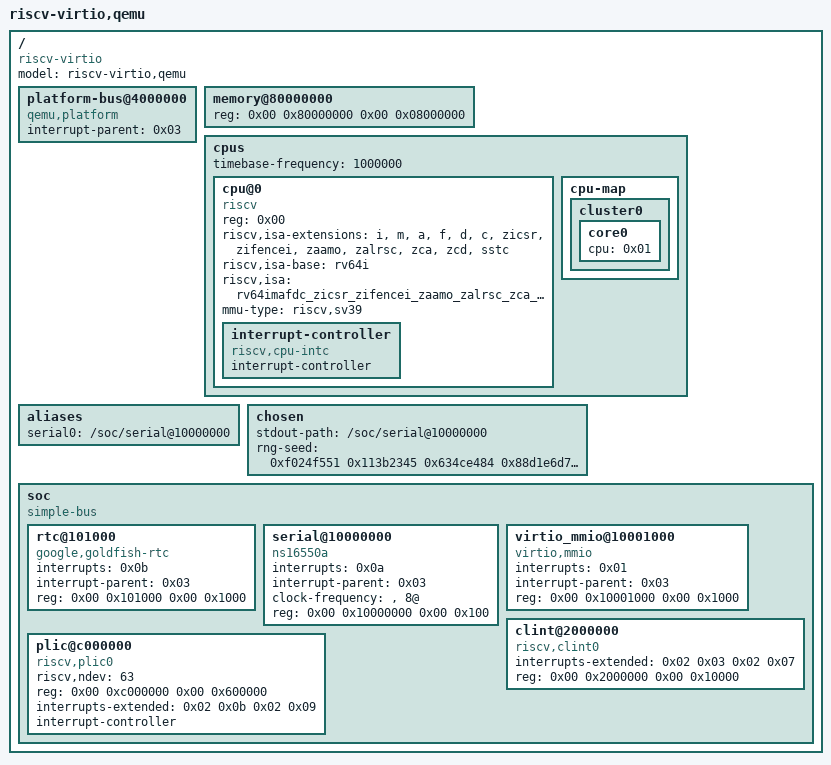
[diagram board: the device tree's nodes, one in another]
/dts-v1/;

/ {
	#address-cells = <0x02>;
	#size-cells = <0x02>;
	compatible = "riscv-virtio";
	model = "riscv-virtio,qemu";

	platform-bus@4000000 {
		interrupt-parent = <0x03>;
		ranges = <0x00 0x00 0x4000000 0x2000000>;
		#address-cells = <0x01>;
		#size-cells = <0x01>;
		compatible = "qemu,platform", "simple-bus";
	};

	memory@80000000 {
		device_type = "memory";
		reg = <0x00 0x80000000 0x00 0x08000000>;
	};

	cpus {
		#address-cells = <0x01>;
		#size-cells = <0x00>;
		timebase-frequency = <1000000>; // 1MHz

		cpu@0 {
			phandle = <0x01>;
			device_type = "cpu";
			reg = <0x00>;
			status = "okay";
			compatible = "riscv";
			riscv,isa-extensions = "i", "m", "a", "f", "d", "c","zicsr", "zifencei", "zaamo", "zalrsc", "zca", "zcd", "sstc";
			riscv,isa-base = "rv64i";
			riscv,isa = "rv64imafdc_zicsr_zifencei_zaamo_zalrsc_zca_zcd_sstc";
			mmu-type = "riscv,sv39";

			interrupt-controller {
				#interrupt-cells = <0x01>;
				interrupt-controller;
				compatible = "riscv,cpu-intc";
				phandle = <0x02>;
			};
		};

		cpu-map {
			cluster0 {
				core0 {
					cpu = <0x01>;
				};
			};
		};
	};

	aliases {
		serial0 = "/soc/serial@10000000";
	};

	chosen {
		stdout-path = "/soc/serial@10000000";
		rng-seed = <0xf024f551 0x113b2345 0x634ce484 0x88d1e6d7 0x4ef455c6 0x78c102fc 0x4ff7a80c 0x13bb7a>;
	};

	soc {
		#address-cells = <0x02>;
		#size-cells = <0x02>;
		compatible = "simple-bus";
		ranges;

		rtc@101000 {
			interrupts = <0x0b>;
			interrupt-parent = <0x03>;
			reg = <0x00 0x101000 0x00 0x1000>;
			compatible = "google,goldfish-rtc";
		};

		serial@10000000 {
			interrupts = <0x0a>;
			interrupt-parent = <0x03>;
			clock-frequency = "", "8@";
			reg = <0x00 0x10000000 0x00 0x100>;
			compatible = "ns16550a";
		};

		virtio_mmio@10001000 {
			interrupts = <0x01>;
			interrupt-parent = <0x03>;
			reg = <0x00 0x10001000 0x00 0x1000>;
			compatible = "virtio,mmio";
		};

		clint@2000000 {
			interrupts-extended = <0x02 0x03 0x02 0x07>;
			reg = <0x00 0x2000000 0x00 0x10000>;
			compatible = "riscv,clint0";
		};

		plic@c000000 {
			phandle = <0x03>;
			riscv,ndev = <63>;
			reg = <0x00 0xc000000 0x00 0x600000>;
			interrupts-extended = <0x02 0x0b 0x02 0x09>;
			interrupt-controller;
			compatible = "riscv,plic0";
			#address-cells = <0x00>;
			#interrupt-cells = <0x01>;
		};
	};
};
